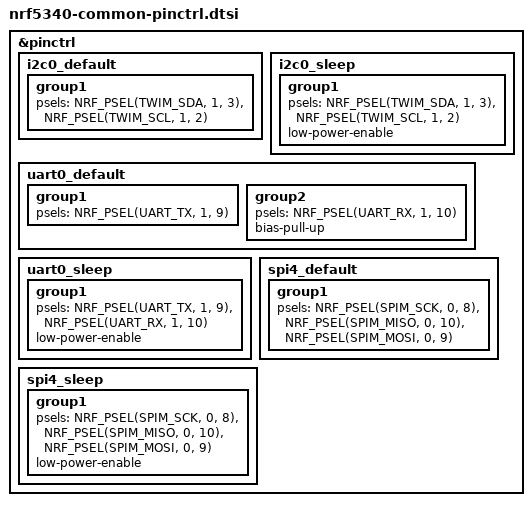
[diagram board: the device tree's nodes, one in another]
/*
 * Copyright (c) 2022 Nordic Semiconductor
 * SPDX-License-Identifier: Apache-2.0
 */

&pinctrl {
	i2c0_default: i2c0_default {
		group1 {
			psels = <NRF_PSEL(TWIM_SDA, 1, 3)>,
				<NRF_PSEL(TWIM_SCL, 1, 2)>;
		};
	};

	i2c0_sleep: i2c0_sleep {
		group1 {
			psels = <NRF_PSEL(TWIM_SDA, 1, 3)>,
				<NRF_PSEL(TWIM_SCL, 1, 2)>;
			low-power-enable;
		};
	};

	uart0_default: uart0_default {
		group1 {
			psels = <NRF_PSEL(UART_TX, 1, 9)>;
		};
		group2 {
			psels = <NRF_PSEL(UART_RX, 1, 10)>;
			bias-pull-up;
		};
	};

	uart0_sleep: uart0_sleep {
		group1 {
			psels = <NRF_PSEL(UART_TX, 1, 9)>,
				<NRF_PSEL(UART_RX, 1, 10)>;
			low-power-enable;
		};
	};

	spi4_default: spi4_default {
		group1 {
			psels = <NRF_PSEL(SPIM_SCK, 0, 8)>,
				<NRF_PSEL(SPIM_MISO, 0, 10)>,
				<NRF_PSEL(SPIM_MOSI, 0, 9)>;
		};
	};

	spi4_sleep: spi4_sleep {
		group1 {
			psels = <NRF_PSEL(SPIM_SCK, 0, 8)>,
				<NRF_PSEL(SPIM_MISO, 0, 10)>,
				<NRF_PSEL(SPIM_MOSI, 0, 9)>;
			low-power-enable;
		};
	};

};
